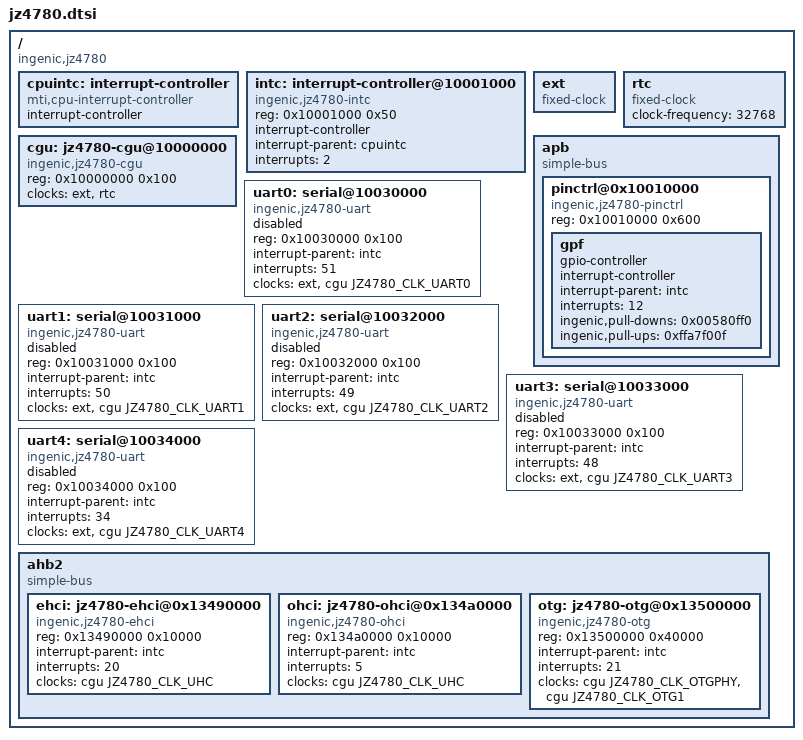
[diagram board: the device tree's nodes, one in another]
#include <dt-bindings/clock/jz4780-cgu.h>

/ {
	#address-cells = <1>;
	#size-cells = <1>;
	compatible = "ingenic,jz4780";

	cpuintc: interrupt-controller {
		#address-cells = <0>;
		#interrupt-cells = <1>;
		interrupt-controller;
		compatible = "mti,cpu-interrupt-controller";
	};

	intc: interrupt-controller@10001000 {
		compatible = "ingenic,jz4780-intc";
		reg = <0x10001000 0x50>;

		interrupt-controller;
		#interrupt-cells = <1>;

		interrupt-parent = <&cpuintc>;
		interrupts = <2>;
	};

	ext: ext {
		compatible = "fixed-clock";
		#clock-cells = <0>;
	};

	rtc: rtc {
		compatible = "fixed-clock";
		#clock-cells = <0>;
		clock-frequency = <32768>;
	};

	cgu: jz4780-cgu@10000000 {
		compatible = "ingenic,jz4780-cgu";
		reg = <0x10000000 0x100>;

		clocks = <&ext>, <&rtc>;
		clock-names = "ext", "rtc";

		#clock-cells = <1>;
	};

    apb {
        compatible = "simple-bus";
        #address-cells = <1>;
        #size-cells = <1>;
        ranges = <>;

        pinctrl@0x10010000 {
            compatible = "ingenic,jz4780-pinctrl";
            reg = <0x10010000 0x600>;

            gpf: gpf {
                gpio-controller;
                #gpio-cells = <2>;

                interrupt-controller;
                #interrupt-cells = <2>;

                interrupt-parent = <&intc>;
                interrupts = <12>;

                ingenic,pull-downs = <0x00580ff0>;
                ingenic,pull-ups   = <0xffa7f00f>;
            };
        };
    };

	uart0: serial@10030000 {
		compatible = "ingenic,jz4780-uart";
		reg = <0x10030000 0x100>;

		interrupt-parent = <&intc>;
		interrupts = <51>;

		clocks = <&ext>, <&cgu JZ4780_CLK_UART0>;
		clock-names = "baud", "module";

		status = "disabled";
	};

	uart1: serial@10031000 {
		compatible = "ingenic,jz4780-uart";
		reg = <0x10031000 0x100>;

		interrupt-parent = <&intc>;
		interrupts = <50>;

		clocks = <&ext>, <&cgu JZ4780_CLK_UART1>;
		clock-names = "baud", "module";

		status = "disabled";
	};

	uart2: serial@10032000 {
		compatible = "ingenic,jz4780-uart";
		reg = <0x10032000 0x100>;

		interrupt-parent = <&intc>;
		interrupts = <49>;

		clocks = <&ext>, <&cgu JZ4780_CLK_UART2>;
		clock-names = "baud", "module";

		status = "disabled";
	};

	uart3: serial@10033000 {
		compatible = "ingenic,jz4780-uart";
		reg = <0x10033000 0x100>;

		interrupt-parent = <&intc>;
		interrupts = <48>;

		clocks = <&ext>, <&cgu JZ4780_CLK_UART3>;
		clock-names = "baud", "module";

		status = "disabled";
	};

	uart4: serial@10034000 {
		compatible = "ingenic,jz4780-uart";
		reg = <0x10034000 0x100>;

		interrupt-parent = <&intc>;
		interrupts = <34>;

		clocks = <&ext>, <&cgu JZ4780_CLK_UART4>;
		clock-names = "baud", "module";

		status = "disabled";
	};

    ahb2 {
        compatible = "simple-bus";
        #address-cells = <1>;
        #size-cells = <1>;
        ranges = <>;

        ehci: jz4780-ehci@0x13490000 {
            compatible = "ingenic,jz4780-ehci";
            reg = <0x13490000 0x10000>;

            interrupt-parent = <&intc>;
            interrupts = <20>;

            clocks = <&cgu JZ4780_CLK_UHC>;
        };

        ohci: jz4780-ohci@0x134a0000 {
            compatible = "ingenic,jz4780-ohci";
            reg = <0x134a0000 0x10000>;

            interrupt-parent = <&intc>;
            interrupts = <5>;

            clocks = <&cgu JZ4780_CLK_UHC>;
            clock-names = "uhc";
        };

        otg: jz4780-otg@0x13500000 {
            compatible = "ingenic,jz4780-otg";
            reg = <0x13500000 0x40000>;

            interrupt-parent = <&intc>;
            interrupts = <21>;

            clocks = <&cgu JZ4780_CLK_OTGPHY>, <&cgu JZ4780_CLK_OTG1>;
            clock-names = "otg_phy", "otg1";
        };
    };
};
